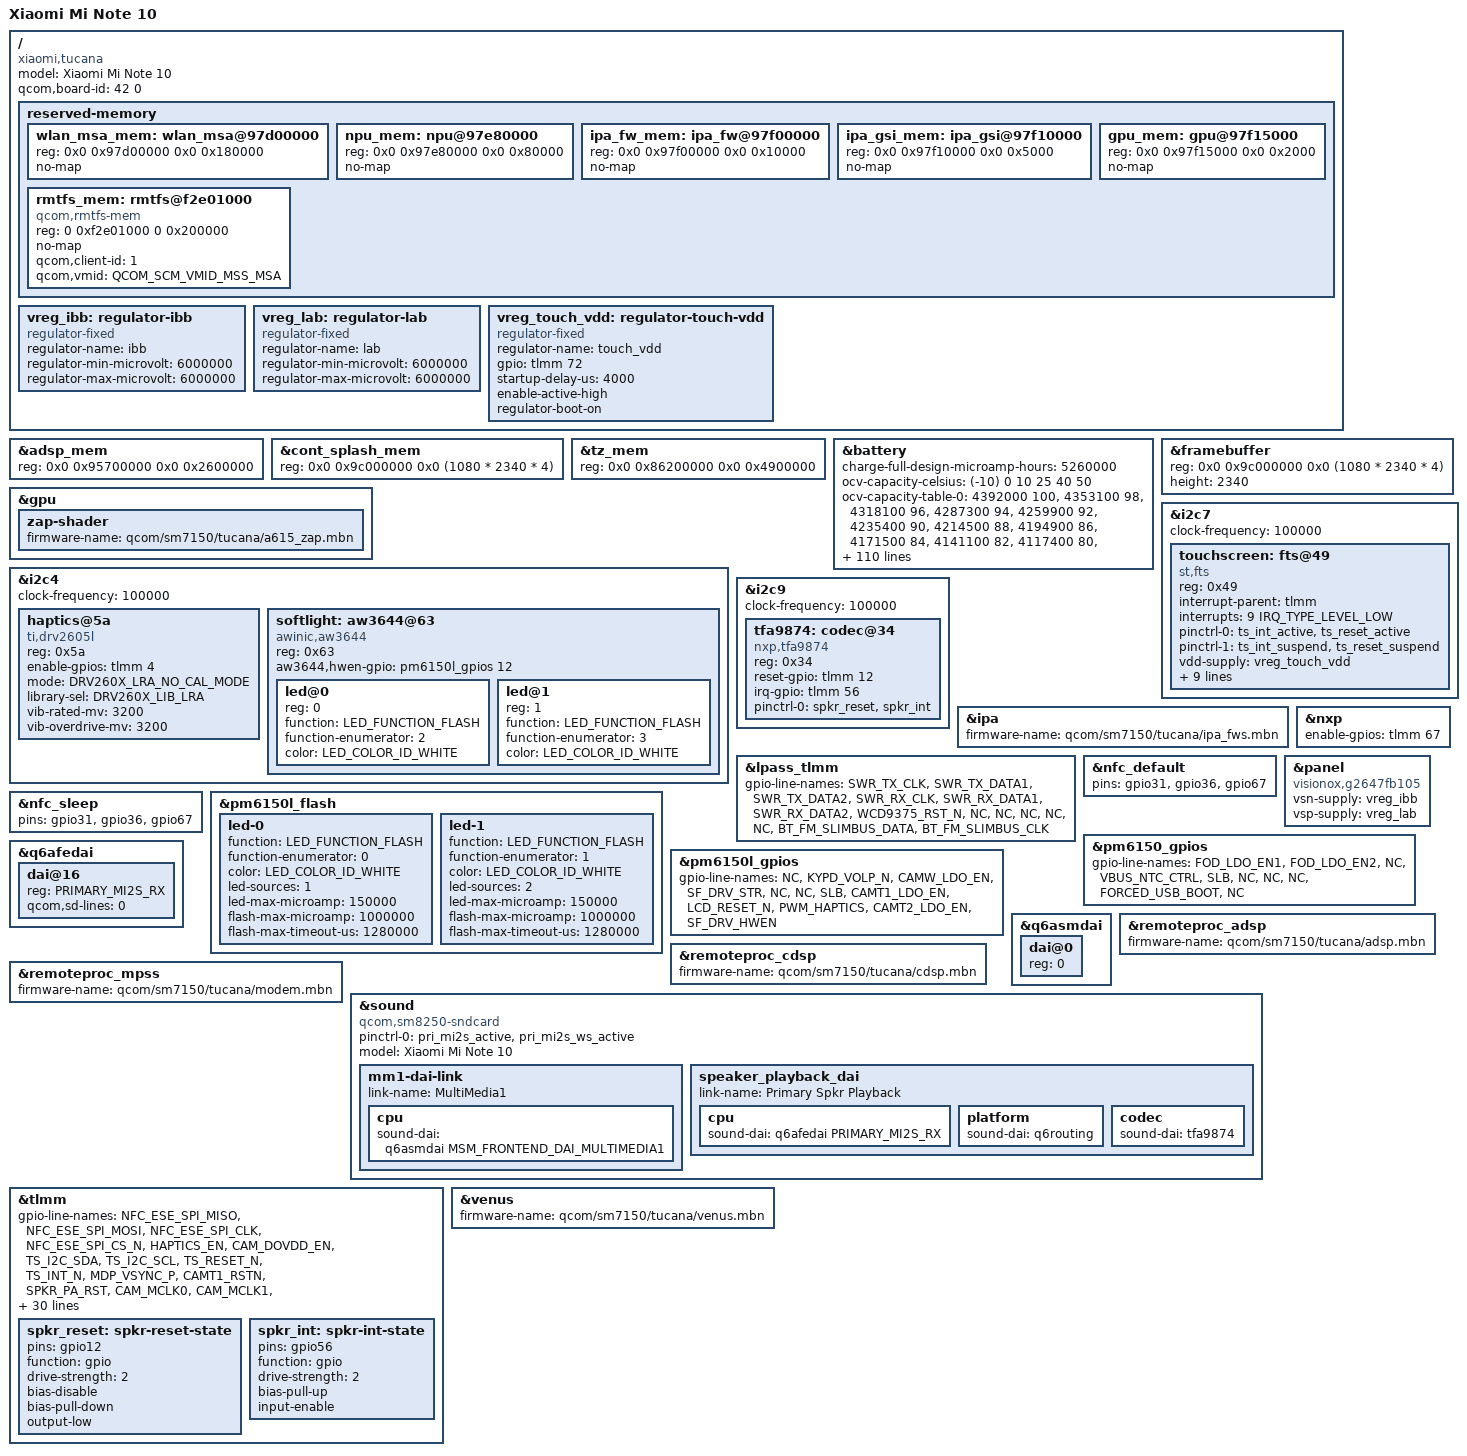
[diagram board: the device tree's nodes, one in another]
// SPDX-License-Identifier: BSD-3-Clause
/*
 * Copyright (c) 2024, Danila Tikhonov <danila@jiaxyga.com>
 * Copyright (c) 2024, Alexander Baransky <alexander.baranskiy@yandex.ru>
 */

/dts-v1/;

#include "sm7150-xiaomi-common.dtsi"
#include <dt-bindings/input/ti-drv260x.h>

/delete-node/ &wlan_msa_mem;
/delete-node/ &npu_mem;
/delete-node/ &ipa_fw_mem;
/delete-node/ &ipa_gsi_mem;
/delete-node/ &gpu_mem;

&adsp_mem {
	reg = <0x0 0x95700000 0x0 0x2600000>;
};

&cont_splash_mem {
	reg = <0x0 0x9c000000 0x0 (1080 * 2340 * 4)>;
};

&tz_mem {
	reg = <0x0 0x86200000 0x0 0x4900000>;
};

/ {
	/*
	 * Xiaomi Mi Note 10 (Xiaomi Mi CC9 Pro)
	 * Xiaomi Mi Note 10 Pro (Xiaomi Mi CC9 Pro Premium Edition)
	 */
	model = "Xiaomi Mi Note 10";
	compatible = "xiaomi,tucana", "qcom,sm7150";

	qcom,board-id = <42 0>;

	reserved-memory {
		wlan_msa_mem: wlan_msa@97d00000 {
			reg = <0x0 0x97d00000 0x0 0x180000>;
			no-map;
		};

		npu_mem: npu@97e80000 {
			reg = <0x0 0x97e80000 0x0 0x80000>;
			no-map;
		};

		ipa_fw_mem: ipa_fw@97f00000 {
			reg = <0x0 0x97f00000 0x0 0x10000>;
			no-map;
		};

		ipa_gsi_mem: ipa_gsi@97f10000 {
			reg = <0x0 0x97f10000 0x0 0x5000>;
			no-map;
		};

		gpu_mem: gpu@97f15000 {
			reg = <0x0 0x97f15000 0x0 0x2000>;
			no-map;
		};

		rmtfs_mem: rmtfs@f2e01000 {
			compatible = "qcom,rmtfs-mem";
			reg = <0 0xf2e01000 0 0x200000>;
			no-map;

			qcom,client-id = <1>;
			qcom,vmid = <QCOM_SCM_VMID_MSS_MSA>;
		};
	};

	vreg_ibb: regulator-ibb {
		compatible = "regulator-fixed";
		regulator-name = "ibb";
		regulator-min-microvolt = <6000000>;
		regulator-max-microvolt = <6000000>;
	};

	vreg_lab: regulator-lab {
		compatible = "regulator-fixed";
		regulator-name = "lab";
		regulator-min-microvolt = <6000000>;
		regulator-max-microvolt = <6000000>;
	};

	vreg_touch_vdd: regulator-touch-vdd {
		compatible = "regulator-fixed";
		regulator-name = "touch_vdd";
		gpio = <&tlmm 72 GPIO_ACTIVE_HIGH>;
		startup-delay-us = <4000>;
		enable-active-high;
		regulator-boot-on;
	};
};

&battery {
	charge-full-design-microamp-hours = <5260000>;
	ocv-capacity-celsius = <(-10) 0 10 25 40 50>;
	ocv-capacity-table-0 = <4392000 100>, <4353100 98>, <4318100 96>, <4287300 94>, <4259900 92>, <4235400 90>,
				<4214500 88>, <4194900 86>, <4171500 84>, <4141100 82>, <4117400 80>, <4108300 78>,
				<4102100 76>, <4087000 74>, <4041100 72>, <3993700 70>, <3967500 68>, <3947500 66>,
				<3928800 64>, <3911500 62>, <3895100 60>, <3878200 58>, <3861600 56>, <3848100 54>,
				<3837300 52>, <3828200 50>, <3820500 48>, <3814000 46>, <3808200 44>, <3803100 42>,
				<3798400 40>, <3793700 38>, <3789200 36>, <3784500 34>, <3779700 32>, <3774600 30>,
				<3769300 28>, <3763600 26>, <3757000 24>, <3749100 22>, <3740200 20>, <3730800 18>,
				<3720800 16>, <3711900 14>, <3703600 12>, <3694700 10>, <3689700 9>, <3684400 8>,
				<3677900 7>, <3666500 6>, <3644000 5>, <3603100 4>, <3543900 3>, <3457500 2>,
				<3314700 1>, <2976900 0>;
	ocv-capacity-table-1 = <4390000 100>, <4356800 98>, <4326000 96>, <4298000 94>, <4272800 92>, <4248600 90>,
				<4224200 88>, <4200400 86>, <4178000 84>, <4156800 82>, <4136200 80>, <4116100 78>,
				<4096200 76>, <4075800 74>, <4054800 72>, <4032600 70>, <4006300 68>, <3977900 66>,
				<3955000 64>, <3937500 62>, <3921300 60>, <3903800 58>, <3886200 56>, <3870500 54>,
				<3856700 52>, <3844100 50>, <3831600 48>, <3819700 46>, <3810400 44>, <3803500 42>,
				<3797900 40>, <3793400 38>, <3789700 36>, <3786100 34>, <3782600 32>, <3779100 30>,
				<3775300 28>, <3771500 26>, <3766400 24>, <3758300 22>, <3748100 20>, <3737700 18>,
				<3726300 16>, <3713400 14>, <3700200 12>, <3690400 10>, <3686700 9>, <3682500 8>,
				<3677700 7>, <3668200 6>, <3647700 5>, <3607900 4>, <3550000 3>, <3470700 2>,
				<3345800 1>, <3098200 0>;
	ocv-capacity-table-2 = <4388500 100>, <4358600 98>, <4330500 96>, <4304300 94>, <4279900 92>, <4256100 90>,
				<4232400 88>, <4209000 86>, <4186100 84>, <4163700 82>, <4141700 80>, <4120600 78>,
				<4100000 76>, <4079500 74>, <4059000 72>, <4038500 70>, <4017800 68>, <3997100 66>,
				<3976500 64>, <3955600 62>, <3935200 60>, <3915200 58>, <3895900 56>, <3879500 54>,
				<3865400 52>, <3852800 50>, <3841300 48>, <3831000 46>, <3821700 44>, <3813500 42>,
				<3806000 40>, <3798400 38>, <3791200 36>, <3785600 34>, <3781800 32>, <3778000 30>,
				<3773600 28>, <3768900 26>, <3763100 24>, <3756400 22>, <3748400 20>, <3738500 18>,
				<3726500 16>, <3712200 14>, <3699200 12>, <3691500 10>, <3689300 9>, <3686900 8>,
				<3683400 7>, <3674600 6>, <3648500 5>, <3599700 4>, <3534700 3>, <3443900 2>,
				<3305700 1>, <2807600 0>;
	ocv-capacity-table-3 = <4386000 100>, <4357400 98>, <4330300 96>, <4304700 94>, <4280700 92>, <4257200 90>,
				<4233600 88>, <4210200 86>, <4187200 84>, <4164500 82>, <4142100 80>, <4120100 78>,
				<4098500 76>, <4077900 74>, <4058100 72>, <4038600 70>, <4018300 68>, <3998200 66>,
				<3980400 64>, <3965300 62>, <3948800 60>, <3926500 58>, <3902200 56>, <3883500 54>,
				<3868600 52>, <3855900 50>, <3844600 48>, <3834500 46>, <3825400 44>, <3816900 42>,
				<3809200 40>, <3802100 38>, <3795600 36>, <3789300 34>, <3783400 32>, <3777200 30>,
				<3770400 28>, <3763200 26>, <3755800 24>, <3748400 22>, <3740400 20>, <3730900 18>,
				<3719700 16>, <3706000 14>, <3694400 12>, <3688800 10>, <3687100 9>, <3685600 8>,
				<3682200 7>, <3673000 6>, <3641600 5>, <3592000 4>, <3526500 3>, <3435400 2>,
				<3292300 1>, <2806200 0>;
	ocv-capacity-table-4 = <4382000 100>, <4353800 98>, <4327100 96>, <4301800 94>, <4277900 92>, <4254500 90>,
				<4231100 88>, <4207900 86>, <4185000 84>, <4162400 82>, <4140100 80>, <4118300 78>,
				<4096900 76>, <4076400 74>, <4056500 72>, <4037100 70>, <4017800 68>, <3999000 66>,
				<3981500 64>, <3966000 62>, <3949200 60>, <3927200 58>, <3903000 56>, <3884200 54>,
				<3869300 52>, <3856500 50>, <3845300 48>, <3835400 46>, <3826300 44>, <3817900 42>,
				<3810200 40>, <3803200 38>, <3796800 36>, <3790200 34>, <3783800 32>, <3776700 30>,
				<3767300 28>, <3756300 26>, <3747000 24>, <3739400 22>, <3731600 20>, <3722200 18>,
				<3711400 16>, <3697800 14>, <3687100 12>, <3682200 10>, <3681200 9>, <3679500 8>,
				<3676500 7>, <3665600 6>, <3633400 5>, <3583600 4>, <3518900 3>, <3427700 2>,
				<3295400 1>, <2820300 0>;
	ocv-capacity-table-5 = <4380500 100>, <4352500 98>, <4325900 96>, <4300800 94>, <4277200 92>, <4253900 90>,
				<4230500 88>, <4207300 86>, <4184400 84>, <4161800 82>, <4139600 80>, <4117700 78>,
				<4096300 76>, <4075800 74>, <4055900 72>, <4036700 70>, <4017900 68>, <3999700 66>,
				<3982400 64>, <3966400 62>, <3949300 60>, <3927500 58>, <3903700 56>, <3884900 54>,
				<3870000 52>, <3857100 50>, <3845700 48>, <3835600 46>, <3826400 44>, <3817800 42>,
				<3810000 40>, <3803000 38>, <3796400 36>, <3789600 34>, <3782700 32>, <3774900 30>,
				<3764300 28>, <3751700 26>, <3741300 24>, <3733200 22>, <3725300 20>, <3715800 18>,
				<3705100 16>, <3691600 14>, <3681100 12>, <3676700 10>, <3675700 9>, <3674300 8>,
				<3670900 7>, <3657900 6>, <3624000 5>, <3573200 4>, <3508000 3>, <3416600 2>,
				<3279200 1>, <2823300 0>;
};

&framebuffer {
	reg = <0x0 0x9c000000 0x0 (1080 * 2340 * 4)>;
	height = <2340>;
};

&gpu {
	zap-shader {
		firmware-name = "qcom/sm7150/tucana/a615_zap.mbn";
	};
};

&i2c4 {
	clock-frequency = <100000>;
	status = "okay";

	haptics@5a {
		compatible = "ti,drv2605l";
		reg = <0x5a>;
		enable-gpios = <&tlmm 4 GPIO_ACTIVE_HIGH>;
		mode = <DRV260X_LRA_NO_CAL_MODE>;
		library-sel = <DRV260X_LIB_LRA>;
		vib-rated-mv = <3200>;
		vib-overdrive-mv = <3200>;
	};

	softlight: aw3644@63 {
		compatible = "awinic,aw3644";
		reg = <0x63>;
		aw3644,hwen-gpio = <&pm6150l_gpios 12 GPIO_ACTIVE_HIGH>;
		#address-cells = <1>;
		#size-cells = <0>;

		led@0 {
			reg = <0>;
			function = LED_FUNCTION_FLASH;
			function-enumerator = <2>;
			color = <LED_COLOR_ID_WHITE>;
		};

		led@1 {
			reg = <1>;
			function = LED_FUNCTION_FLASH;
			function-enumerator = <3>;
			color = <LED_COLOR_ID_WHITE>;
		};
	};
};

&i2c7 {
	clock-frequency = <100000>;
	status = "okay";

	touchscreen: fts@49 {
		compatible = "st,fts";
		reg = <0x49>;

		interrupt-parent = <&tlmm>;
		interrupts = <9 IRQ_TYPE_LEVEL_LOW>;

		pinctrl-0 = <&ts_int_active &ts_reset_active>;
		pinctrl-1 = <&ts_int_suspend &ts_reset_suspend>;
		pinctrl-names = "default", "sleep";

		vdd-supply = <&vreg_touch_vdd>;
		avdd-supply = <&vreg_l6c_3p0>;
		fts,regulator_dvdd = "vdd";
		fts,regulator_avdd = "avdd";

		fts,irq-gpio = <&tlmm 9 GPIO_TRANSITORY>;
		fts,irq-flags = <0x2008>; /* oneshot and trigger low */

		fts,reset-gpio-enable;
		fts,reset-gpio = <&tlmm 8 GPIO_ACTIVE_HIGH>;

		fts,x-max = <1080>;
		fts,y-max = <2340>;
	};
	/* goodix,gt9886 (touchscreen) @ 5d */
};

&i2c9 {
	clock-frequency = <100000>;
	status = "okay";

	tfa9874: codec@34 {
		compatible = "nxp,tfa9874";
		reg = <0x34>;

		reset-gpio = <&tlmm 12 GPIO_ACTIVE_HIGH>;
		irq-gpio = <&tlmm 56 GPIO_ACTIVE_HIGH>;

		pinctrl-names = "default";
		pinctrl-0 = <&spkr_reset &spkr_int>;

		#sound-dai-cells = <0>;
	};
	/* ti,bq2597x (charger) @ 66 */
};

&ipa {
	firmware-name = "qcom/sm7150/tucana/ipa_fws.mbn";
};

&lpass_tlmm {
	gpio-line-names = "SWR_TX_CLK", /* GPIO_0 */
			  "SWR_TX_DATA1",
			  "SWR_TX_DATA2",
			  "SWR_RX_CLK",
			  "SWR_RX_DATA1",
			  "SWR_RX_DATA2",
			  "WCD9375_RST_N",
			  "NC",
			  "NC",
			  "NC",
			  "NC", /* GPIO_10 */
			  "NC",
			  "BT_FM_SLIMBUS_DATA",
			  "BT_FM_SLIMBUS_CLK";
};

&nfc_default {
	pins = "gpio31", "gpio36", "gpio67";
};

&nfc_sleep {
	pins = "gpio31", "gpio36", "gpio67";
};

&nxp {
	enable-gpios = <&tlmm 67 GPIO_ACTIVE_HIGH>;
};

&panel {
	compatible = "visionox,g2647fb105";

	vsn-supply = <&vreg_ibb>;
	vsp-supply = <&vreg_lab>;
};

&pm6150l_flash {
	status = "okay";

	led-0 {
		function = LED_FUNCTION_FLASH;
		function-enumerator = <0>;
		color = <LED_COLOR_ID_WHITE>;
		led-sources = <1>;
		led-max-microamp = <150000>;
		flash-max-microamp = <1000000>;
		flash-max-timeout-us = <1280000>;
	};

	led-1 {
		function = LED_FUNCTION_FLASH;
		function-enumerator = <1>;
		color = <LED_COLOR_ID_WHITE>;
		led-sources = <2>;
		led-max-microamp = <150000>;
		flash-max-microamp = <1000000>;
		flash-max-timeout-us = <1280000>;
	};
};

&pm6150_gpios {
	gpio-line-names = "FOD_LDO_EN1", /* GPIO_1 */
			  "FOD_LDO_EN2",
			  "NC",
			  "VBUS_NTC_CTRL",
			  "SLB",
			  "NC",
			  "NC",
			  "NC",
			  "FORCED_USB_BOOT",
			  "NC";  /* GPIO_10 */
};

&pm6150l_gpios {
	gpio-line-names = "NC", /* GPIO_1 */
			  "KYPD_VOLP_N",
			  "CAMW_LDO_EN",
			  "SF_DRV_STR",
			  "NC",
			  "NC",
			  "SLB",
			  "CAMT1_LDO_EN",
			  "LCD_RESET_N",
			  "PWM_HAPTICS", /* GPIO_10 */
			  "CAMT2_LDO_EN",
			  "SF_DRV_HWEN";
};

&q6afedai {
	dai@16 {
		reg = <PRIMARY_MI2S_RX>;
		qcom,sd-lines = <0>;
	};
};

&q6asmdai {
	dai@0 {
		reg = <0>;
	};
};

&remoteproc_adsp {
	firmware-name = "qcom/sm7150/tucana/adsp.mbn";
};

&remoteproc_cdsp {
	firmware-name = "qcom/sm7150/tucana/cdsp.mbn";
};

&remoteproc_mpss {
	firmware-name = "qcom/sm7150/tucana/modem.mbn";
};

&sound {
	compatible = "qcom,sm8250-sndcard";
	pinctrl-0 = <&pri_mi2s_active &pri_mi2s_ws_active>;
	pinctrl-names = "default";
	model = "Xiaomi Mi Note 10";

	mm1-dai-link {
		link-name = "MultiMedia1";
		cpu {
			sound-dai = <&q6asmdai MSM_FRONTEND_DAI_MULTIMEDIA1>;
		};
	};

	speaker_playback_dai {
		link-name = "Primary Spkr Playback";
		cpu {
			sound-dai = <&q6afedai PRIMARY_MI2S_RX>;
		};

		platform {
			sound-dai = <&q6routing>;
		};

		codec {
			sound-dai = <&tfa9874>;
		};
	};
};

&tlmm {
	gpio-line-names = "NFC_ESE_SPI_MISO", /* GPIO_0 */
			  "NFC_ESE_SPI_MOSI",
			  "NFC_ESE_SPI_CLK",
			  "NFC_ESE_SPI_CS_N",
			  "HAPTICS_EN",
			  "CAM_DOVDD_EN",
			  "TS_I2C_SDA",
			  "TS_I2C_SCL",
			  "TS_RESET_N",
			  "TS_INT_N",
			  "MDP_VSYNC_P", /* GPIO_10 */
			  "CAMT1_RSTN",
			  "SPKR_PA_RST",
			  "CAM_MCLK0",
			  "CAM_MCLK1",
			  "CAM_MCLK2",
			  "CAM_MCLK3",
			  "CCI_I2C_SDA0",
			  "CCI_I2C_SCL0",
			  "CCI_I2C_SDA1",
			  "CCI_I2C_SCL1", /* GPIO_20 */
			  "CAMM_LDO_EN",
			  "FL_STROBE_TRIG",
			  "CAMF_RSTN",
			  "CAMM_RSTN",
			  "CAMU_RSTN",
			  "CAMW_RSTN",
			  "CCI_I2C_SDA2",
			  "CCI_I2C_SCL2",
			  "CAMU_LDO_EN",
			  "CAMT2_RSTN",  /* GPIO_30 */
			  "NFC_LABBCLK3_EN",
			  "ERR_INT_N",
			  "LCD_ID_DET1",
			  "NFC_I2C_SDA",
			  "NFC_I2C_SCL",
			  "NFC_DWL_REQ",
			  "NFC_IRQ",
			  "BT_UART_CTS",
			  "BT_UART_RFR",
			  "BT_UART_TX", /* GPIO_40 */
			  "BT_UART_RX",
			  "NC",
			  "INFARED_SPI_MOSI",
			  "BLSP2_UART_TX",
			  "BLSP2_UART_RX",
			  "APPS_I2C_SDA",
			  "APPS_I2C_SCL",
			  "FORCED_USB_BOOT",
			  "SPKR_I2S_BCK",
			  "SPKR_I2S_WS", /* GPIO_50 */
			  "SPKR_I2S_DOUT",
			  "SPKR_I2S_DIN1",
			  "TYPC_I2C_SDA",
			  "TYPC_I2C_SCL",
			  "LCD_ID_DET2",
			  "SPKR_INT",
			  "CAMF_LDO_EN",
			  "BQ25970_MASTER_INT",
			  "FOD_SPI_MISO",
			  "FOD_SPI_MOSI", /* GPIO_60 */
			  "FOD_SPI_SCLK",
			  "FOD_SPI_CS_N",
			  "FOD_LDO_EN",
			  "GPOUT",
			  "FOD_RST",
			  "SF_DRV_TX",
			  "NFC_ENABLE",
			  "TOF_INT",
			  "FOD_INT",
			  "RFFE6_CLK", /* GPIO_70 */
			  "RFFE6_DATA",
			  "TP_VDDI_EN",
			  "WLAN_SW_CTRL",
			  "GRFC_4",
			  "UIM2_DATA",
			  "UIM2_CLK",
			  "UIM2_RESET",
			  "UIM2_PRESENT",
			  "UIM1_DATA",
			  "UIM1_CLK", /* GPIO_80 */
			  "UIM1_RESET",
			  "UIM1_PRESENT",
			  "GRFC_8",
			  "GRFC_9",
			  "WMSS_RESET_N",
			  "ACCEL_INT",
			  "GYRO_INT",
			  "MIPI_SEL1",
			  "ALS_INT_N",
			  "MIPI_SEL2", /* GPIO_90 */
			  "SF_DRV_TORCH",
			  "RFFE4_CLK",
			  "NC",
			  "SW_IO",
			  "GRFC_3",
			  "QLINK_REQUEST",
			  "QLINK_ENABLE",
			  "GRFC_2",
			  "NC",
			  "NC", /* GPIO_100 */
			  "RFFE3_DATA",
			  "RFFE3_CLK",
			  "RFFE4_DATA",
			  "USB_PHY_PS",
			  "RFFE5_DATA",
			  "RFFE5_CLK",
			  "GRFC_5",
			  "WLAN_COEX_UART_TXD",
			  "WLAN_COEX_UART_RXD",
			  "GRFC_34", /* GPIO_110 */
			  "GRFC_33",
			  "RFFE1_DATA",
			  "RFFE1_CLK";

	spkr_reset: spkr-reset-state {
		pins = "gpio12";
		function = "gpio";
		drive-strength = <2>;
		bias-disable;
		bias-pull-down;
		output-low;
	};

	spkr_int: spkr-int-state {
		pins = "gpio56";
		function = "gpio";
		drive-strength = <2>;
		bias-pull-up;
		input-enable;
	};
};

&venus {
	firmware-name = "qcom/sm7150/tucana/venus.mbn";
};
